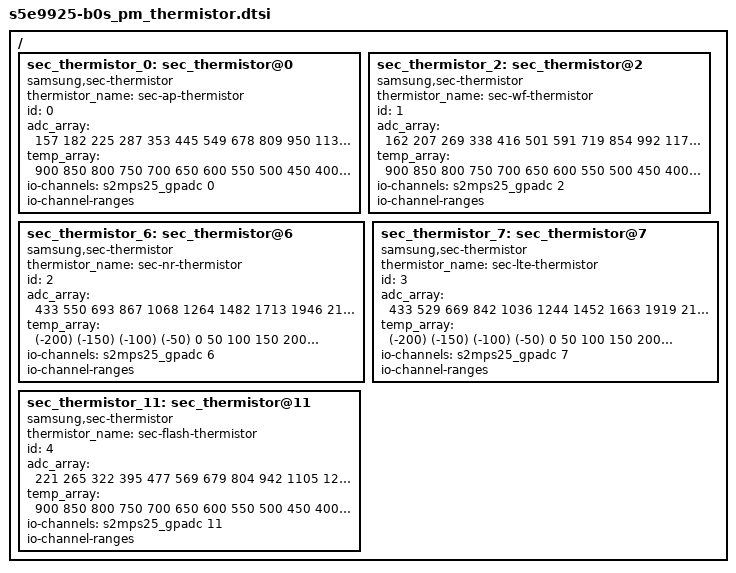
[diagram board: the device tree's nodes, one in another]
/*
 * SAMSUNG S5E9925 Power Management device tree source
 *
 * Copyright (c) 2021 Samsung Electronics Co., Ltd.
 *		http://www.samsung.com
 *
 * This program is free software; you can redistribute it and/or modify
 * it under the terms of the GNU General Public License version 2 as
 * published by the Free Software Foundation.
 */

/ {
	fragment@model {
		target-path = "/";
		__overlay__ {
			sec_thermistor_0: sec_thermistor@0 {
				compatible = "samsung,sec-thermistor";
				status = "okay";
				thermistor_name = "sec-ap-thermistor";
				id = <0>;

				adc_array = <157 182 225 287 353 445 549 678 809 950
					1139 1328 1515 1722 1937 2175 2420 2669 2887 3070
					3246 3402 3520>;
				temp_array = <900 850 800 750 700 650 600 550 500 450
					  400 350 300 250 200 150 100 50 0 (-50)
					  (-100) (-150) (-200)>;

				io-channels = <&s2mps25_gpadc 0>;
				io-channel-names = "adc-ap-temp";
				io-channel-ranges;
			};

			sec_thermistor_2: sec_thermistor@2 {
				compatible = "samsung,sec-thermistor";
				status = "okay";
				thermistor_name = "sec-wf-thermistor";
				id = <1>;

				adc_array = <162 207 269 338 416 501 591 719 854 992
					1173 1360 1565 1794 2029 2244 2470 2689 2901 3104
					3267 3413 3497>;
				temp_array = <900 850 800 750 700 650 600 550 500 450
					  400 350 300 250 200 150 100 50 0 (-50)
					  (-100) (-150) (-200)>;

				io-channels = <&s2mps25_gpadc 2>;
				io-channel-names = "adc-wf-temp";
				io-channel-ranges;
			};

			sec_thermistor_6: sec_thermistor@6 {
				compatible = "samsung,sec-thermistor";
				status = "okay";
				thermistor_name = "sec-nr-thermistor";
				id = <2>;

				adc_array = <433 550 693 867 1068 1264 1482 1713 1946 2185
					2433 2661 2858 3048 3196 3340 3473 3567 3655 3738
					3795 3831 3858>;
				temp_array = <(-200) (-150) (-100) (-50) 0 50 100 150 200 250
					300 350 400 450 500 550 600 650 700 750
					800 850 900>;

				io-channels = <&s2mps25_gpadc 6>;
				io-channel-names = "adc-nr-temp";
				io-channel-ranges;
			};

			sec_thermistor_7: sec_thermistor@7 {
				compatible = "samsung,sec-thermistor";
				status = "okay";
				thermistor_name = "sec-lte-thermistor";
				id = <3>;

				adc_array = <433 529 669 842 1036 1244 1452 1663 1919 2178
					2411 2635 2833 3019 3176 3317 3464 3561 3652 3734
					3799 3842 3880>;
				temp_array = <(-200) (-150) (-100) (-50) 0 50 100 150 200 250
					300 350 400 450 500 550 600 650 700 750
					800 850 900>;

				io-channels = <&s2mps25_gpadc 7>;
				io-channel-names = "adc-lte-temp";
				io-channel-ranges;
			};

			sec_thermistor_11: sec_thermistor@11 {
				compatible = "samsung,sec-thermistor";
				status = "okay";
				thermistor_name = "sec-flash-thermistor";
				id = <4>;

				adc_array = <221 265 322 395 477 569 679 804 942 1105
					1281 1466 1684 1915 2155 2392 2634 2845 3044 3227
					3412 3530 3649>;
				temp_array = <900 850 800 750 700 650 600 550 500 450
					  400 350 300 250 200 150 100 50 0 (-50)
					  (-100) (-150) (-200)>;

				io-channels = <&s2mps25_gpadc 11>;
				io-channel-names = "adc-flash-temp";
				io-channel-ranges;
			};
		}; /* end of __overlay__ */
	}; /* end of fragment */
}; /* end of root */
